# MKE14Z7 register map
Vendor: Freescale Semiconductor, Inc.; Series: Kinetis_E; File version: 1.6
CPU: CM0PLUS r0p0, little endian, no MPU, no FPU, VTOR, 2 interrupt priority bits
Registers are 32-bit, read-write, reset 0x0 unless marked. A register's access mark holds for its fields unless they carry their own. Offsets are from the block's base; [hi:lo] are bit positions; {n}, {i} and the like mark numbered series; 'fields as' and 'values as' point back to an identical list.

## TRGMUX0 — TRGMUX
Base 0x40062000
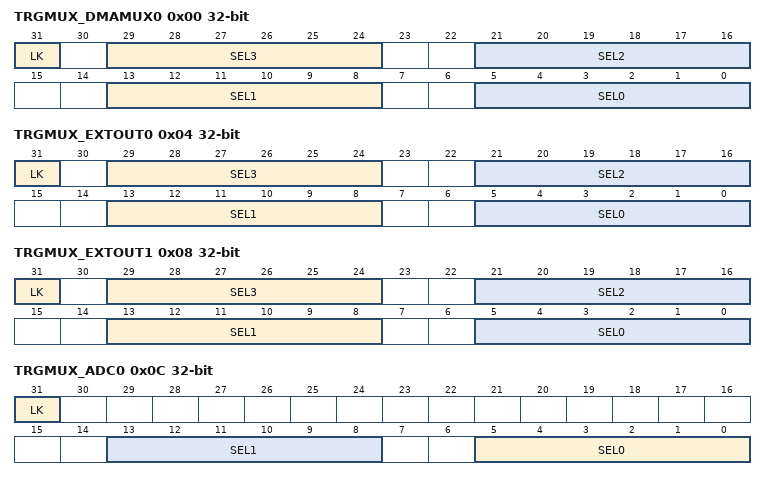
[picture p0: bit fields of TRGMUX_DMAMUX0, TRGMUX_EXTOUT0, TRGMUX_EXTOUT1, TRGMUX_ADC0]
0x00 TRGMUX_DMAMUX0 — TRGMUX Register
  [31] LK ro — Enable
    0=Register can be written; 1=Register cannot be written until the next system Reset
  [8n+5:8n] SEL{n} (n=0..3) — Trigger MUX Input {n} Source Select
0x04 TRGMUX_EXTOUT0 — TRGMUX Register
  fields as TRGMUX_DMAMUX0
0x08 TRGMUX_EXTOUT1 — TRGMUX Register
  fields as TRGMUX_DMAMUX0
0x0C TRGMUX_ADC0 — TRGMUX Register
  [31] LK ro — Enable
    values as TRGMUX_DMAMUX0.LK
  [13:8] SEL1 — Trigger MUX Input 1 Source Select
  [5:0] SEL0 — Trigger MUX Input 0 Source Select
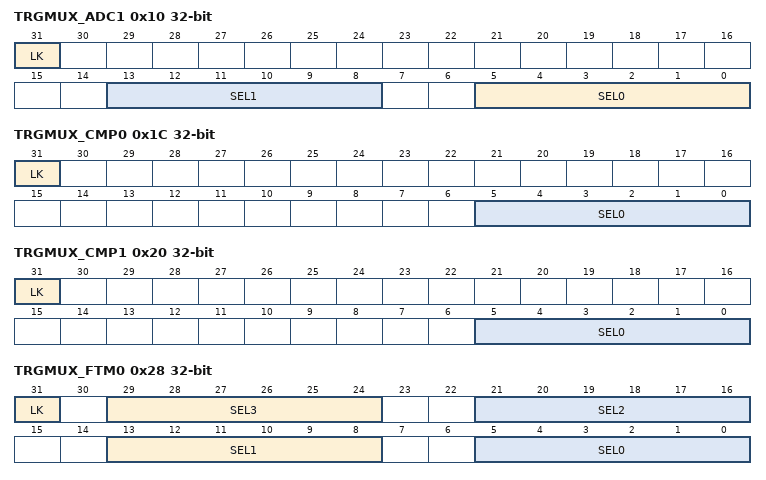
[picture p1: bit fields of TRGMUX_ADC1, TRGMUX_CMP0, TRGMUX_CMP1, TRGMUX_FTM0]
0x10 TRGMUX_ADC1 — TRGMUX Register
  fields as TRGMUX_ADC0
0x1C TRGMUX_CMP0 — TRGMUX Register
  [31] LK ro — Enable
    values as TRGMUX_DMAMUX0.LK
  [5:0] SEL0 — Trigger MUX Input 0 Source Select
0x20 TRGMUX_CMP1 — TRGMUX Register
  fields as TRGMUX_CMP0
0x28 TRGMUX_FTM0 — TRGMUX Register
  fields as TRGMUX_DMAMUX0
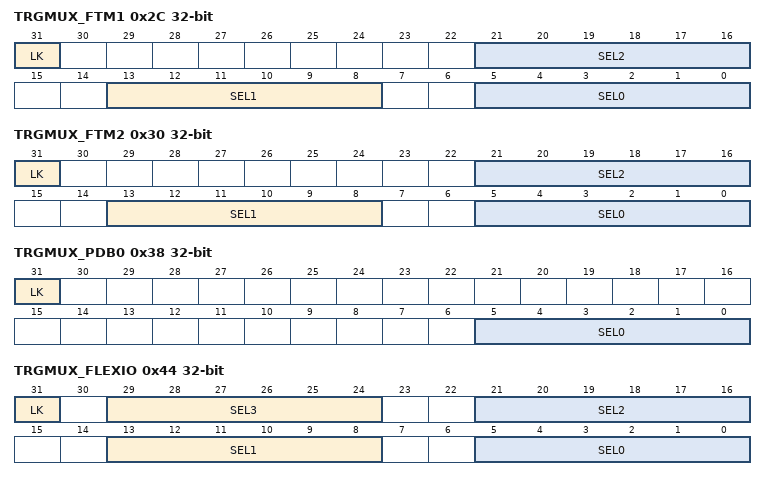
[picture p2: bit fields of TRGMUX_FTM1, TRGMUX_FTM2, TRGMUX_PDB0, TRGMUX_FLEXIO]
0x2C TRGMUX_FTM1 — TRGMUX Register
  [31] LK ro — Enable
    values as TRGMUX_DMAMUX0.LK
  [21:16] SEL2 — Trigger MUX Input 2 Source Select
  [13:8] SEL1 — Trigger MUX Input 1 Source Select
  [5:0] SEL0 — Trigger MUX Input 0 Source Select
0x30 TRGMUX_FTM2 — TRGMUX Register
  fields as TRGMUX_FTM1
0x38 TRGMUX_PDB0 — TRGMUX Register
  fields as TRGMUX_CMP0
0x44 TRGMUX_FLEXIO — TRGMUX Register
  fields as TRGMUX_DMAMUX0
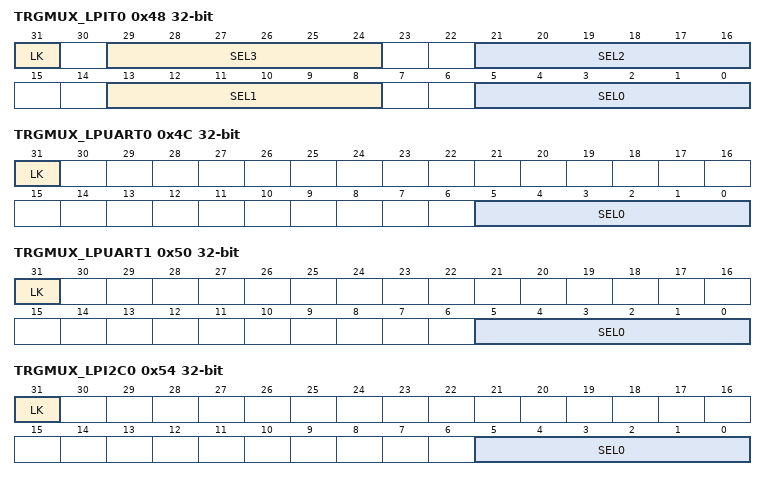
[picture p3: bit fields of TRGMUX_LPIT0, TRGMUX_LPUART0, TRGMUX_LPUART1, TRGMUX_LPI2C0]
0x48 TRGMUX_LPIT0 — TRGMUX Register
  fields as TRGMUX_DMAMUX0
0x4C TRGMUX_LPUART0 — TRGMUX Register
  fields as TRGMUX_CMP0
0x50 TRGMUX_LPUART1 — TRGMUX Register
  fields as TRGMUX_CMP0
0x54 TRGMUX_LPI2C0 — TRGMUX Register
  fields as TRGMUX_CMP0
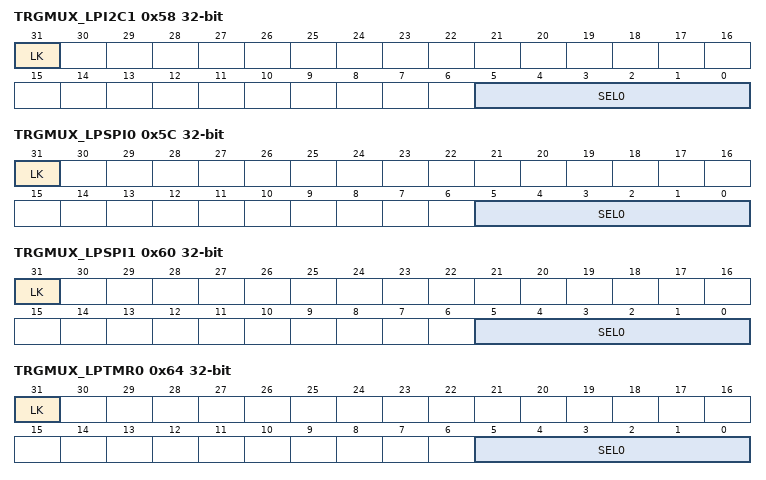
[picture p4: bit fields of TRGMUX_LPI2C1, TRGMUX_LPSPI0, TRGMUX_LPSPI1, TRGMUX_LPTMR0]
0x58 TRGMUX_LPI2C1 — TRGMUX Register
  fields as TRGMUX_CMP0
0x5C TRGMUX_LPSPI0 — TRGMUX Register
  fields as TRGMUX_CMP0
0x60 TRGMUX_LPSPI1 — TRGMUX Register
  fields as TRGMUX_CMP0
0x64 TRGMUX_LPTMR0 — TRGMUX Register
  fields as TRGMUX_CMP0
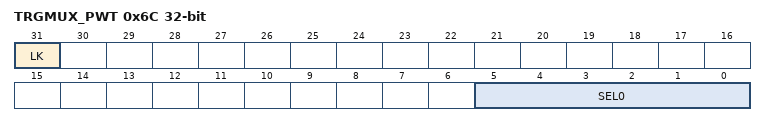
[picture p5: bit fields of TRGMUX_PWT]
0x6C TRGMUX_PWT — TRGMUX Register
  fields as TRGMUX_CMP0

## TRGMUX1 — TRGMUX
Base 0x40063000
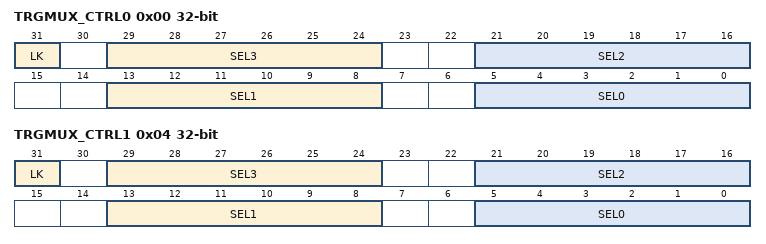
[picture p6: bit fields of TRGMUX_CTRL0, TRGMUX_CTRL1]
0x00 TRGMUX_CTRL0 — TRGMUX Register
  [31] LK ro — Enable
    0=Register can be written; 1=Register cannot be written until the next system Reset
  [8n+5:8n] SEL{n} (n=0..3) — Trigger MUX Input {n} Source Select
0x04 TRGMUX_CTRL1 — TRGMUX Register
  fields as TRGMUX_CTRL0

## PCC
Base 0x40065000
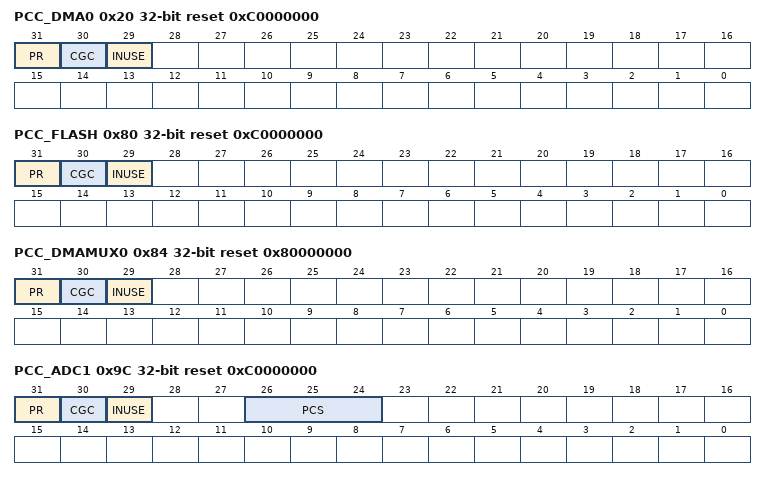
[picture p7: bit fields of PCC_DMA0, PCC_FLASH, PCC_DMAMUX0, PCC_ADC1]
0x20 PCC_DMA0 reset 0xC0000000 — PCC Register
  [31] PR ro — Enable
    0=Peripheral is not present; 1=Peripheral is present
  [30] CGC — Clock Control
    0=Clock disabled; 1=Clock enabled
  [29] INUSE ro — Clock Gate Control
    0=Peripheral is not being used; 1=Peripheral is being used. Software cannot modify the existing clocking configuration.
0x80 PCC_FLASH reset 0xC0000000 — PCC Register
  fields as PCC_DMA0
0x84 PCC_DMAMUX0 reset 0x80000000 — PCC Register
  fields as PCC_DMA0
0x9C PCC_ADC1 reset 0xC0000000 — PCC Register
  [31] PR ro — Enable
    0=Peripheral is not present; 1=Peripheral is present
  [30] CGC — Clock Control
    0=Clock disabled; 1=Clock enabled
  [29] INUSE ro — Clock Gate Control
    values as PCC_DMA0.INUSE
  [26:24] PCS — Peripheral Clock Source Select
    0=Clock is off (or test clock is enabled); 1=OSCCLK - System Oscillator Bus Clock(scg_sosc_slow_clk); 2=SCGIRCLK - Slow IRC Clock(scg_sirc_slow_clk), (maximum is 8MHz); 3=SCGFIRCLK - Fast IRC Clock(scg_firc_slow_clk), (maximum is 48MHz); 6=SCGPCLK System PLL clock(scg_spll_slow_clk)
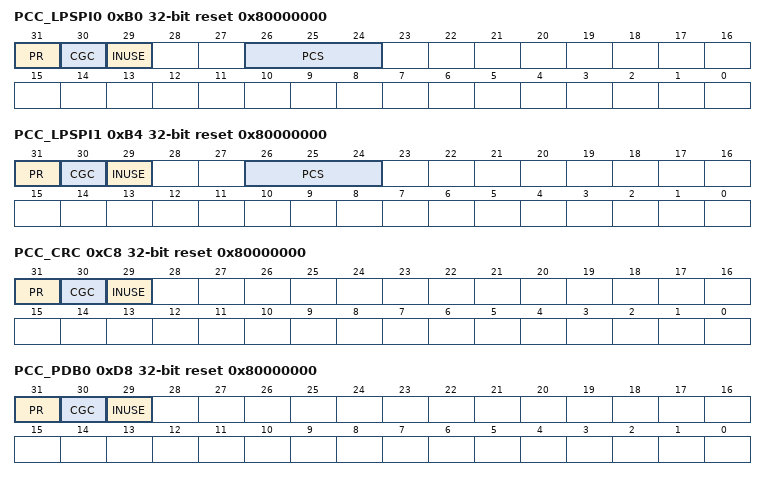
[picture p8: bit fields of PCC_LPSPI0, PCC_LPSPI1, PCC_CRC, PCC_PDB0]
0xB0 PCC_LPSPI0 reset 0x80000000 — PCC Register
  fields as PCC_ADC1
0xB4 PCC_LPSPI1 reset 0x80000000 — PCC Register
  fields as PCC_ADC1
0xC8 PCC_CRC reset 0x80000000 — PCC Register
  fields as PCC_DMA0
0xD8 PCC_PDB0 reset 0x80000000 — PCC Register
  fields as PCC_DMA0
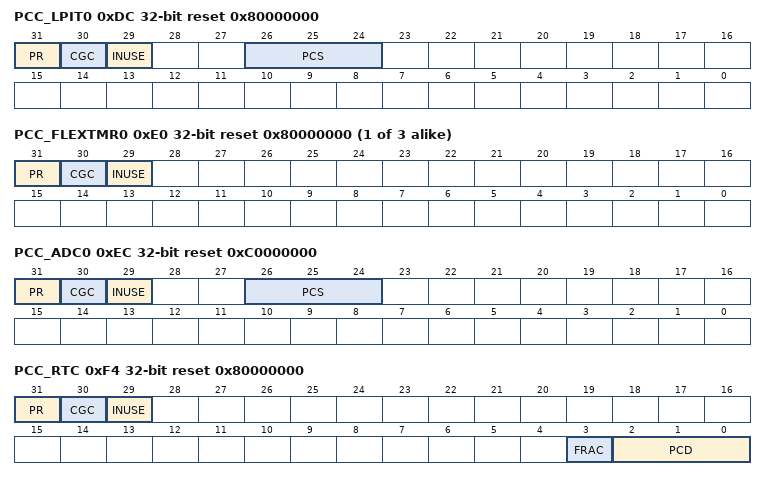
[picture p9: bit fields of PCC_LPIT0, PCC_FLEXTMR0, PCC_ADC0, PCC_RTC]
0xDC PCC_LPIT0 reset 0x80000000 — PCC Register
  fields as PCC_ADC1
{0xE0+4i} PCC_FLEXTMR{i} reset 0x80000000 (i=0..2) — PCC Register
  fields as PCC_DMA0
0xEC PCC_ADC0 reset 0xC0000000 — PCC Register
  fields as PCC_ADC1
0xF4 PCC_RTC reset 0x80000000 — PCC Register
  [31] PR ro — Enable
    0=Peripheral is not present; 1=Peripheral is present
  [30] CGC — Clock Control
    0=Clock disabled; 1=Clock enabled
  [29] INUSE ro — Clock Gate Control
    values as PCC_DMA0.INUSE
  [3] FRAC — Peripheral Clock Divider Fraction
    0=Fractional value is 0; 1=Fractional value is 1
  [2:0] PCD — Peripheral Clock Divider Select
    0=Divide by 1 (pass-through, no clock divide); {v}=Divide by {v+1} (v=1..7)
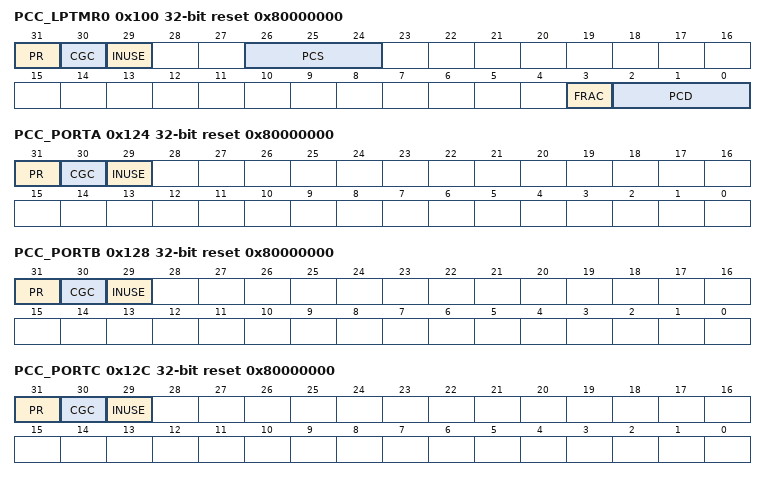
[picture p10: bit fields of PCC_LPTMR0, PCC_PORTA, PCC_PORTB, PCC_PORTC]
0x100 PCC_LPTMR0 reset 0x80000000 — PCC Register
  [31] PR ro — Enable
    0=Peripheral is not present; 1=Peripheral is present
  [30] CGC — Clock Control
    0=Clock disabled; 1=Clock enabled
  [29] INUSE ro — Clock Gate Control
    values as PCC_DMA0.INUSE
  [26:24] PCS — Peripheral Clock Source Select
    values as PCC_ADC1.PCS
  [3] FRAC — Peripheral Clock Divider Fraction
    0=Fractional value is 0; 1=Fractional value is 1
  [2:0] PCD — Peripheral Clock Divider Select
    values as PCC_RTC.PCD
0x124 PCC_PORTA reset 0x80000000 — PCC Register
  fields as PCC_DMA0
0x128 PCC_PORTB reset 0x80000000 — PCC Register
  fields as PCC_DMA0
0x12C PCC_PORTC reset 0x80000000 — PCC Register
  fields as PCC_DMA0
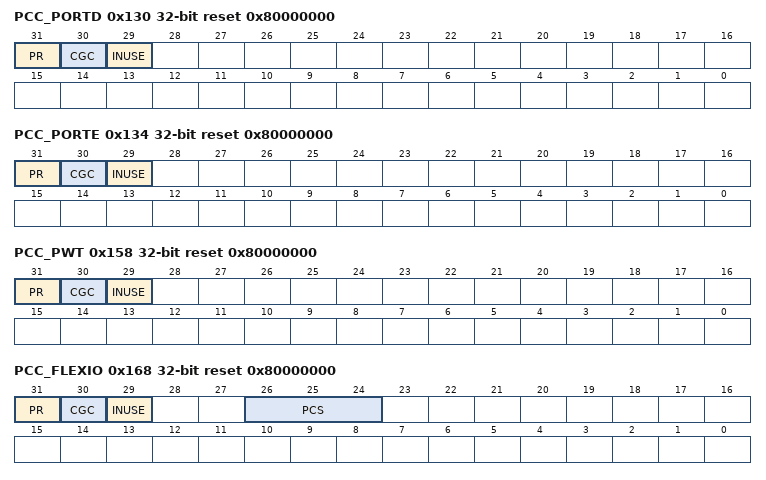
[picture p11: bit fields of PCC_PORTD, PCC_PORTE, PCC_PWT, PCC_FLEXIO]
0x130 PCC_PORTD reset 0x80000000 — PCC Register
  fields as PCC_DMA0
0x134 PCC_PORTE reset 0x80000000 — PCC Register
  fields as PCC_DMA0
0x158 PCC_PWT reset 0x80000000 — PCC Register
  fields as PCC_DMA0
0x168 PCC_FLEXIO reset 0x80000000 — PCC Register
  fields as PCC_ADC1
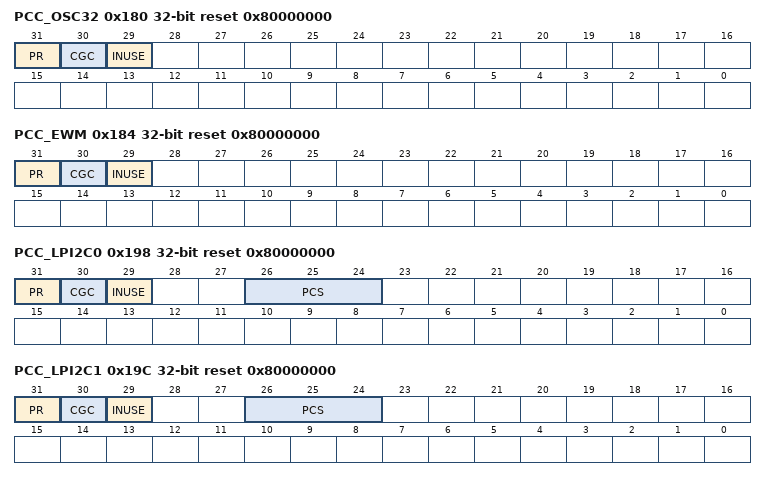
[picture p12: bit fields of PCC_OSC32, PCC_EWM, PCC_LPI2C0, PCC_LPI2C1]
0x180 PCC_OSC32 reset 0x80000000 — PCC Register
  fields as PCC_DMA0
0x184 PCC_EWM reset 0x80000000 — PCC Register
  fields as PCC_DMA0
0x198 PCC_LPI2C0 reset 0x80000000 — PCC Register
  fields as PCC_ADC1
0x19C PCC_LPI2C1 reset 0x80000000 — PCC Register
  fields as PCC_ADC1
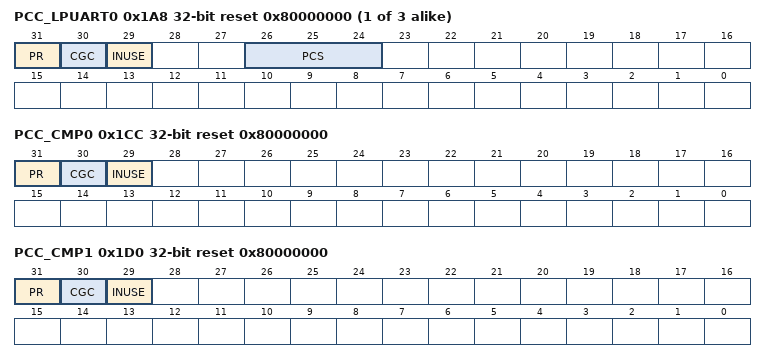
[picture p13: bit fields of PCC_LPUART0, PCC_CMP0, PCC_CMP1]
{0x1A8+4i} PCC_LPUART{i} reset 0x80000000 (i=0..2) — PCC Register
  fields as PCC_ADC1
0x1CC PCC_CMP0 reset 0x80000000 — PCC Register
  fields as PCC_DMA0
0x1D0 PCC_CMP1 reset 0x80000000 — PCC Register
  fields as PCC_DMA0
